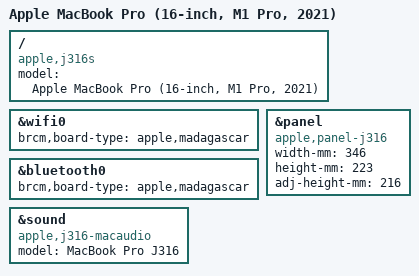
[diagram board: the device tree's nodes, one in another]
// SPDX-License-Identifier: GPL-2.0+ OR MIT
/*
 * MacBook Pro (16-inch, M1 Pro, 2021)
 *
 * target-type: J316s
 *
 * Copyright The Asahi Linux Contributors
 */

/dts-v1/;

#include "t6000.dtsi"
#include "t600x-j314-j316.dtsi"

/ {
	compatible = "apple,j316s", "apple,t6000", "apple,arm-platform";
	model = "Apple MacBook Pro (16-inch, M1 Pro, 2021)";
};

&wifi0 {
	brcm,board-type = "apple,madagascar";
};

&bluetooth0 {
	brcm,board-type = "apple,madagascar";
};

&panel {
	compatible = "apple,panel-j316", "apple,panel-mini-led", "apple,panel";
	width-mm = <346>;
	height-mm = <223>;
	adj-height-mm = <216>;
};

&sound {
	compatible = "apple,j316-macaudio", "apple,macaudio";
	model = "MacBook Pro J316";
};
